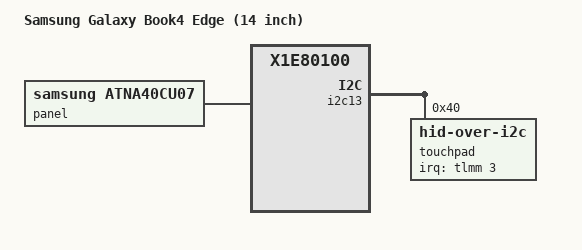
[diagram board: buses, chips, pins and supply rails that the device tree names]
// SPDX-License-Identifier: BSD-3-Clause

/dts-v1/;

#include "x1e-samsung-galaxy-book4-edge.dtsi"

/ {
	model = "Samsung Galaxy Book4 Edge (14 inch)";
	compatible = "samsung,galaxy-book4-edge-14", "samsung,galaxy-book4-edge",
		     "qcom,x1e80100";
};

&ec {
	host-sleep-gpios = <&tlmm 44 GPIO_ACTIVE_LOW>;
	hpd-control-gpios = <&tlmm 49 GPIO_ACTIVE_HIGH>;
};

&i2c13 {
	touchpad@40 {
		compatible = "hid-over-i2c";
		reg = <0x40>;

		hid-descr-addr = <0xe>;
		interrupts-extended = <&tlmm 3 IRQ_TYPE_LEVEL_LOW>;

		pinctrl-0 = <&tpad_default>;
		pinctrl-names = "default";
	};
};

&panel {
	compatible = "samsung,atna40cu07", "samsung,atna33xc20";
};

&tlmm {
	gpio-reserved-ranges = <35 1>, <45 3>;
};
